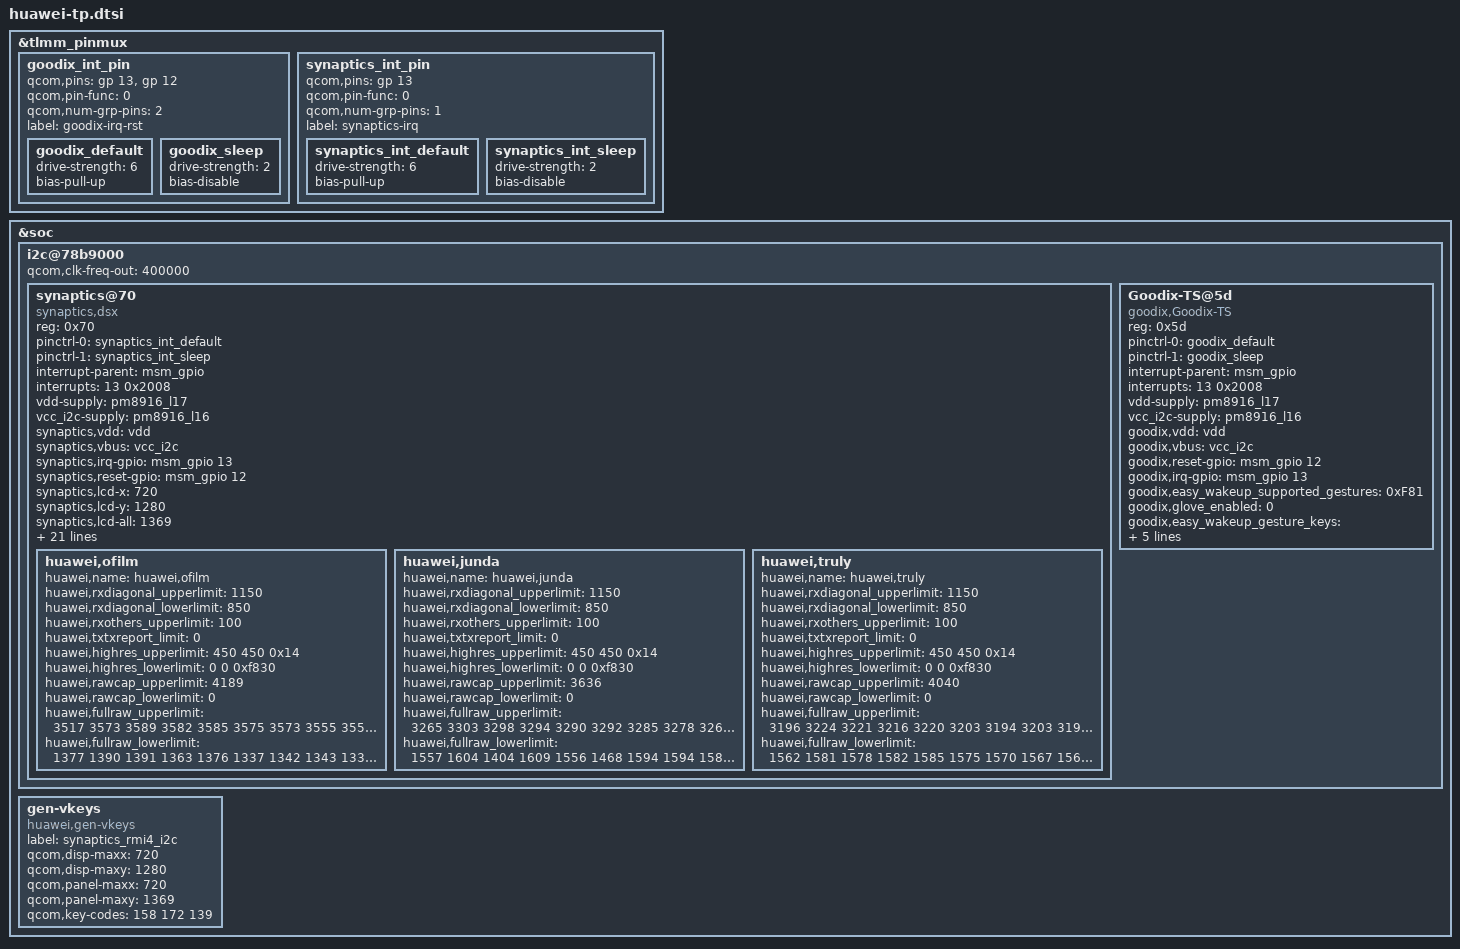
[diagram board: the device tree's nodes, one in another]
/*Add synaptics new driver "Synaptics DSX I2C V2.0"*/
/*Change i2c frepuence from 100kHZ to 400kHZ*/
/*Open fast-relax config for better gesture performance*/
/*Add doze wakeup threshold param for tempreture performance*/
/* Add the pinctrl for the irq and rst*/
&tlmm_pinmux {

	goodix_int_pin {
		qcom,pins = <&gp 13>,<&gp 12>;
		qcom,pin-func = <0>;
		qcom,num-grp-pins = <2>;
		label = "goodix-irq-rst";
		goodix_default: goodix_default {
			drive-strength = <6>;
			bias-pull-up;
		};
		goodix_sleep: goodix_sleep {
			drive-strength = <2>;
			bias-disable;
		};
	};
	synaptics_int_pin {
		qcom,pins = <&gp 13>;
		qcom,pin-func = <0>;
		qcom,num-grp-pins = <1>;
		label = "synaptics-irq";
		synaptics_int_default: synaptics_int_default {
			drive-strength = <6>;
			bias-pull-up;
		};
		synaptics_int_sleep: synaptics_int_sleep {
			drive-strength = <2>;
			bias-disable;
		};
	};
};
&soc {
	i2c@78b9000 { /* BLSP1 QUP5 */
		status = "ok";
		#address-cells = <1>;
		#size-cells = <0>;
		qcom,clk-freq-out = <400000>;
		synaptics@70 {
			compatible = "synaptics,dsx";
			reg = <0x70>;
			pinctrl-names = "active","sleep";
			pinctrl-0 = <&synaptics_int_default>;
			pinctrl-1 = <&synaptics_int_sleep>;
			interrupt-parent = <&msm_gpio>;
			interrupts = <13 0x2008>;
			vdd-supply = <&pm8916_l17>;
			vcc_i2c-supply = <&pm8916_l16>;
			/* Some of qcom's param will not be replaced by huawei in dtb, */
			/* just ignore them:such as "pinctrl-names","pinctrl-0","pinctrl-1", */
			/* "synaptics,display-coords","synaptics,panel-coords","synaptics,i2c-pull-up", */
			/* "synaptics,power-down","synaptics,disable-gpios"*/
			synaptics,vdd = "vdd";
			synaptics,vbus = "vcc_i2c";
			synaptics,irq-gpio = <&msm_gpio 13 0x2008>;
			synaptics,reset-gpio = <&msm_gpio 12 0x0>;

			synaptics,lcd-x = <720>;
			synaptics,lcd-y = <1280>;
			synaptics,lcd-all = <1369>;
			synaptics,virtual_keys = /* KeyCode CenterX CenterY Width Height */
				/* KEY_BACK */
				<158 142 1342 150 100
				/* KEY_HOME(172) */
				172 360 1342 150 100
				/* KEY_MENU */
				139 578 1342 150 100>;

			/* SYNAPTICS_WAKE_UP_GESTURE_FLAG:'1'->enabled,'0'->disabled */
			/*IC flash is not enough for holster,so fw del one gesture*/
			synaptics,gesture_enabled = <0>;
			/* Gestures that supported:                           */
			/* bit0  Double tap                                        */
			/* bit1  Single finger slide from left to right     */
			/* bit2  Single finger slide from right to left     */
			/* bit3  Single finger slide from top to bottom  */
			/* bit4  Single finger slide from bottom to top  */
			/* bit5  Double finger slide from top to bottom--disable for holster*/
			/* bit6  Single finger slide circle                     */
			/* bit7  Single finger write letter c                  */
			/* bit8  Single finger write letter e                  */
			/* bit9  Single finger write letter m                 */
			/* bit10 Single finger write letter w                 */
			/* bit11 Palm off screen                                */
			synaptics,easy_wakeup_supported_gestures = <0xF81>;

			/*Defination of report key value  for different gestures*/
			synaptics,easy_wakeup_gesture_keys = 
			<	143 /*0.Double tap:KEY_WAKEUP*/
				60 /*1.Single finger slide from left to right*/
				61 /*2.Single finger slide from right to left:KEY_F3*/
				62 /*3.Single finger slide from top to bottom*/
				63 /*4.Single finger slide from bottom to top:KEY_F5*/
				64 /*5.Single finger slide circle clockwise*/
				65 /*6.Single finger slide circle counter-clockwise*/
				66 /*7.Single finger write letter c*/
				67 /*8.Single finger write letter e:KEY_F9*/
				68 /*9.Single finger write letter m*/
				87 /*10.Single finger write letter w:KEY_F11*/
				88 /*11.Palm off screen*/
			>;

			/* Double-tap-zone defined by huawei */
			/* Shielded area is:1cm left,1cm right,3cm up,2cm down */
			huawei,dtz_x0 = <116>;
			huawei,dtz_y0 = <349>;
			huawei,dtz_x1 = <604>;
			huawei,dtz_y1 = <1047>;

			/* SYNAPTICS_GLOVE_FUNCTION_FLAG:'1'->enabled,'0'->disabled*/
			synaptics,glove_enabled = <0>;
			/*After reduce power-consumption by exit reduce mode,*/
			/*we have to reduce f-r rate to make sure gesture work fine*/
			synaptics,fast_relax_gesture = <12>;
			/*Holster support flag*/
			/*synaptics,holster_supported = <0>;*/
			/*dwt represent doze wakeup threshold in gesture mode*/
			synaptics,ofilm_dwt = <30>;
			synaptics,truly_dwt = <30>;
			synaptics,junda_dwt = <30>;

			synaptics,reset-on-status = <0>;
			synaptics,power-delay-ms = <160>;
			synaptics,reset-delay-ms = <100>;
			synaptics,reset-active-ms = <90>;
			synaptics,product_name = "g620S";

			/*capacitance self-adapt*/
			/*To adjust the cutting angle threshold to the maximum range*/
			huawei,ofilm {
				huawei,name = "huawei,ofilm";
				huawei,rxdiagonal_upperlimit = <1150>;
				huawei,rxdiagonal_lowerlimit = <850>;
				huawei,rxothers_upperlimit = <100>;
				huawei,txtxreport_limit = <0>;
				huawei,highres_upperlimit = <450 450 0x14>;/*0x14==20*/
				huawei,highres_lowerlimit = <0 0 0xf830>;/*0xf830==-2000*/
				huawei,rawcap_upperlimit = <4189>;
				huawei,rawcap_lowerlimit = <0>;

				huawei,fullraw_upperlimit =
					<3517 3573 3589 3582 3585 3575 3573 3555 3556 3554 3543 3520 4191 3894 3866 3902 3872 3831 3823 3836 3837 3801 3799 9999
					3578 3651 3654 3650 3658 3653 3638 3620 3623 3617 3608 3580 3671 3659 3655 3692 3706 3660 3664 3684 3682 3655 3673 3637
					3584 3653 3646 3647 3655 3634 3638 3621 3623 3620 3612 3581 3649 3638 3653 3672 3680 3645 3641 3660 3653 3641 3633 3633
					3586 3654 3651 3671 3684 3641 3636 3620 3619 3619 3611 3581 3625 3625 3651 3666 3676 3629 3636 3668 3655 3637 3646 3612
					3588 3656 3651 3688 3679 3638 3630 3617 3617 3619 3611 3589 3610 3611 3625 3634 3651 3619 3615 3654 3637 3606 3637 3578
					3598 3660 3688 3686 3653 3636 3634 3624 3623 3627 3614 3589 3591 3621 3619 3616 3625 3617 3603 3658 3617 3584 3604 3558
					3612 3682 3689 3681 3649 3650 3637 3625 3629 3634 3625 3599 3589 3614 3611 3607 3599 3589 3586 3636 3586 3584 3611 3611
					3615 3689 3697 3651 3662 3656 3651 3642 3641 3645 3628 3615 3581 3599 3602 3603 3597 3590 3562 3614 3597 3598 3593 3562
					3638 3692 3669 3660 3669 3666 3667 3647 3650 3647 3636 3617 3575 3601 3588 3599 3599 3578 3559 3594 3606 3567 3586 3533
					3628 3695 3689 3682 3686 3680 3685 3667 3669 3662 3654 3627 3585 3595 3584 3581 3582 3584 3584 3593 3567 3547 3578 3530
					3638 3719 3711 3703 3707 3689 3690 3682 3689 3680 3669 3653 3584 3591 3607 3590 3582 3606 3584 3582 3559 3565 3560 3559
					3660 3732 3727 3716 3721 3706 3712 3699 3711 3697 3686 3684 3588 3610 3617 3595 3593 3614 3582 3575 3577 3558 3559 3520
					3859 3819 3822 3794 3820 3816 3827 3819 3836 3828 3818 3853 3560 3571 3576 3546 3537 3565 3537 3529 3534 3503 3494 9999>;
				/* modify the lower limit of ofilm according the capacitance data*/
				huawei,fullraw_lowerlimit =
					<1377 1390 1391 1363 1376 1337 1342 1343 1335 1332 1316 1313 1616 1575 1552 1557 1544 1529 1531 1537 1517 1529 1511 0
					1421 1435 1438 1399 1396 1398 1382 1387 1370 1370 1367 1342 1474 1475 1459 1460 1454 1468 1459 1452 1459 1460 1457 1457
					1433 1442 1442 1414 1428 1401 1400 1388 1391 1372 1375 1358 1459 1452 1434 1445 1442 1448 1440 1443 1428 1442 1431 1524
					1420 1435 1439 1405 1410 1377 1386 1384 1376 1374 1358 1352 1424 1429 1412 1400 1401 1411 1384 1414 1396 1400 1407 1417
					1435 1450 1441 1421 1421 1397 1405 1397 1385 1376 1378 1361 1421 1414 1399 1411 1391 1407 1398 1407 1393 1406 1396 1396
					1424 1438 1433 1414 1419 1391 1396 1391 1384 1379 1370 1359 1391 1389 1378 1382 1379 1363 1363 1375 1363 1377 1362 1382
					1474 1487 1480 1464 1456 1447 1428 1429 1417 1410 1410 1380 1403 1406 1398 1403 1392 1396 1382 1390 1381 1384 1372 1514
					1452 1463 1459 1432 1458 1425 1422 1409 1419 1391 1394 1379 1379 1368 1350 1363 1358 1368 1356 1358 1347 1358 1342 1372
					1468 1483 1489 1454 1453 1459 1439 1442 1421 1422 1419 1396 1379 1384 1371 1370 1361 1365 1363 1356 1365 1364 1360 1361
					1504 1526 1515 1508 1504 1487 1491 1483 1478 1472 1463 1446 1393 1401 1385 1386 1377 1368 1364 1381 1367 1366 1376 1383
					1502 1522 1517 1496 1493 1487 1482 1468 1470 1451 1455 1441 1355 1365 1356 1356 1336 1362 1323 1358 1351 1352 1330 1459
					1495 1523 1518 1505 1510 1498 1497 1485 1478 1473 1473 1458 1381 1356 1352 1363 1334 1322 1326 1332 1319 1333 1317 1329
					1537 1558 1566 1540 1554 1526 1535 1536 1530 1521 1514 1517 1344 1342 1323 1335 1328 1321 1315 1326 1310 1319 1290 0>;
			};
			huawei,junda {
				huawei,name = "huawei,junda";
				huawei,rxdiagonal_upperlimit = <1150>;
				huawei,rxdiagonal_lowerlimit = <850>;
				huawei,rxothers_upperlimit = <100>;
				huawei,txtxreport_limit = <0>;
				huawei,highres_upperlimit = <450 450 0x14>;/*0x14==20*/
				huawei,highres_lowerlimit = <0 0 0xf830>;/*0xf830==-2000*/
				huawei,rawcap_upperlimit = <3636>;
				huawei,rawcap_lowerlimit = <0>;

				huawei,fullraw_upperlimit =
					<3265 3303 3298 3294 3290 3292 3285 3278 3265 3283 3282 3270 3638 3565 3543 3551 3529 3519 3520 3517 3504 3502 3503 9999 
					3282 3317 3315 3304 3303 3291 3296 3286 3269 3290 3294 3266 3333 3331 3331 3330 3335 3331 3328 3326 3322 3325 3331 3253 
					3283 3315 3316 3305 3305 3296 3294 3292 3269 3285 3292 3265 3315 3316 3309 3309 3317 3318 3312 3303 3307 3305 3316 3338 
					3289 3325 3329 3318 3318 3303 3303 3298 3274 3296 3302 3273 3303 3303 3292 3303 3303 3298 3303 3298 3295 3299 3304 3221 
					3289 3330 3325 3321 3316 3302 3303 3296 3274 3296 3303 3278 3296 3295 3274 3292 3282 3291 3292 3289 3281 3285 3290 3190 
					3291 3328 3328 3318 3315 3302 3308 3302 3278 3299 3307 3285 3289 3283 3273 3282 3273 3277 3281 3276 3266 3268 3274 3199 
					3300 3338 3338 3328 3320 3312 3312 3309 3287 3304 3312 3292 3278 3272 3261 3268 3264 3268 3265 3259 3251 3257 3269 3363 
					3315 3352 3350 3339 3334 3326 3333 3321 3300 3317 3324 3296 3270 3266 3253 3266 3259 3268 3261 3256 3252 3251 3259 3179 
					3331 3360 3357 3352 3344 3337 3342 3331 3311 3326 3325 3303 3261 3259 3251 3261 3251 3263 3259 3250 3251 3250 3256 3156 
					3341 3372 3372 3367 3357 3348 3356 3347 3321 3337 3338 3315 3257 3259 3250 3260 3250 3259 3251 3248 3246 3247 3251 3191 
					3352 3389 3386 3378 3372 3363 3369 3361 3334 3350 3348 3330 3266 3269 3265 3269 3259 3264 3257 3253 3250 3251 3261 3338 
					3356 3394 3396 3386 3385 3372 3381 3368 3343 3360 3359 3346 3266 3269 3257 3276 3265 3268 3263 3256 3251 3253 3261 3159 
					3468 3520 3532 3529 3526 3508 3520 3515 3487 3513 3515 3543 3265 3270 3261 3282 3274 3276 3269 3261 3259 3259 3260 9999>;

				huawei,fullraw_lowerlimit =
					<1557 1604 1404 1609 1556 1468 1594 1594 1589 1599 1598 1590 1730 1721 1709 1713 1709 1699 1699 1698 1668 1697 1708 0 
					1550 1603 1406 1608 1561 1476 1596 1593 1589 1597 1598 1590 1615 1603 1597 1601 1601 1599 1600 1599 1569 1602 1618 1580 
					1556 1603 1407 1607 1562 1474 1602 1596 1591 1599 1598 1591 1599 1602 1589 1594 1593 1589 1589 1590 1561 1594 1608 1633 
					1555 1605 1410 1612 1568 1481 1607 1600 1594 1601 1601 1590 1590 1598 1585 1589 1589 1585 1583 1584 1557 1588 1604 1567 
					1559 1605 1411 1611 1569 1484 1611 1602 1594 1602 1599 1594 1582 1593 1585 1586 1586 1578 1575 1576 1547 1585 1601 1550 
					1563 1604 1413 1609 1575 1489 1613 1603 1595 1601 1603 1596 1576 1591 1584 1585 1586 1577 1575 1576 1538 1584 1594 1559 
					1566 1604 1414 1610 1582 1498 1610 1604 1596 1603 1604 1596 1569 1589 1582 1587 1587 1579 1575 1577 1532 1583 1593 1648 
					1526 1549 1421 1538 1532 1505 1526 1517 1509 1510 1515 1505 1498 1501 1498 1512 1510 1509 1503 1507 1504 1510 1514 1467 
					1580 1610 1506 1610 1611 1568 1611 1608 1603 1604 1608 1603 1559 1586 1579 1585 1587 1581 1580 1578 1528 1578 1587 1543 
					1585 1620 1591 1612 1614 1612 1616 1613 1606 1608 1612 1608 1556 1587 1577 1584 1585 1582 1578 1577 1524 1580 1587 1561 
					1589 1624 1598 1615 1617 1616 1620 1615 1608 1611 1617 1612 1558 1586 1578 1585 1582 1581 1579 1575 1527 1575 1589 1624 
					1594 1629 1606 1621 1623 1623 1623 1620 1616 1615 1622 1621 1554 1585 1576 1584 1579 1583 1579 1575 1529 1573 1572 1536 
					1666 1695 1680 1702 1701 1694 1699 1694 1692 1694 1685 1647 1559 1583 1455 1586 1575 1581 1577 1575 1529 1570 1559 0 >;
			};
			huawei,truly {
				huawei,name = "huawei,truly";
				huawei,rxdiagonal_upperlimit = <1150>;
				huawei,rxdiagonal_lowerlimit = <850>;
				huawei,rxothers_upperlimit = <100>;
				huawei,txtxreport_limit = <0>;
				huawei,highres_upperlimit = <450 450 0x14>;/*0x14==20*/
				huawei,highres_lowerlimit = <0 0 0xf830>;/*0xf830==-2000*/
				huawei,rawcap_upperlimit = <4040>;
				huawei,rawcap_lowerlimit = <0>;

				huawei,fullraw_upperlimit =
					<3196 3224 3221 3216 3220 3203 3194 3203 3190 3192 3186 3178 3625 3508 3484 3482 3455 3434 3432 3425 3421 3415 3395 9999 
					3194 3217 3218 3214 3217 3195 3185 3194 3185 3178 3181 3172 3268 3253 3257 3268 3250 3239 3237 3231 3225 3226 3218 3194 
					3204 3233 3231 3222 3225 3201 3198 3199 3188 3190 3183 3173 3248 3233 3240 3247 3221 3211 3217 3213 3207 3204 3194 3251 
					3208 3244 3230 3234 3231 3214 3214 3207 3205 3209 3199 3186 3231 3218 3225 3229 3208 3211 3208 3214 3196 3195 3194 3186 
					3214 3248 3234 3239 3233 3218 3218 3214 3203 3201 3205 3198 3226 3208 3212 3208 3198 3199 3199 3209 3191 3196 3192 3156 
					3216 3248 3246 3246 3243 3216 3222 3216 3207 3209 3208 3199 3209 3201 3208 3198 3194 3191 3190 3200 3181 3183 3174 3179 
					3230 3259 3253 3252 3257 3237 3225 3225 3214 3224 3211 3208 3213 3208 3208 3199 3188 3185 3183 3196 3170 3175 3165 3295 
					3242 3273 3253 3259 3272 3246 3234 3231 3234 3234 3221 3213 3205 3198 3198 3192 3186 3186 3175 3188 3160 3159 3153 3162 
					3248 3276 3273 3269 3279 3250 3242 3246 3244 3250 3233 3225 3201 3188 3192 3190 3177 3178 3165 3179 3153 3151 3152 3130 
					3259 3285 3286 3277 3281 3263 3251 3257 3251 3250 3244 3229 3194 3186 3194 3192 3168 3173 3162 3172 3160 3157 3151 3164 
					3274 3296 3298 3283 3294 3273 3264 3273 3269 3260 3253 3251 3186 3183 3182 3188 3165 3165 3161 3177 3155 3152 3144 3307 
					3285 3308 3304 3304 3317 3291 3274 3287 3278 3279 3257 3660 3178 3179 3175 3178 3156 3159 3152 3165 3144 3140 3133 3103 
					3638 3506 3487 3485 3497 3468 3454 3460 3447 3454 3435 4039 3200 3204 3201 3205 3181 3177 3174 3191 3164 3156 3153 9999>;

				huawei,fullraw_lowerlimit =
					<1562 1581 1578 1582 1585 1575 1570 1567 1569 1564 1570 1563 1774 1706 1692 1696 1683 1664 1669 1673 1671 1668 1673 0 
					1557 1575 1575 1575 1577 1568 1561 1564 1567 1559 1566 1557 1589 1582 1583 1586 1579 1564 1570 1575 1575 1575 1581 1572 
					1555 1575 1575 1575 1578 1571 1561 1568 1571 1560 1565 1557 1577 1576 1575 1575 1572 1554 1561 1566 1571 1570 1578 1605 
					1555 1577 1581 1577 1580 1571 1565 1571 1570 1561 1562 1561 1566 1571 1573 1571 1568 1553 1559 1563 1568 1569 1575 1558 
					1559 1576 1580 1580 1580 1573 1568 1570 1571 1561 1564 1561 1563 1565 1568 1569 1568 1553 1557 1562 1568 1566 1571 1541 
					1561 1578 1581 1580 1582 1575 1568 1570 1571 1563 1568 1561 1560 1564 1564 1568 1565 1554 1559 1561 1565 1561 1566 1559 
					1565 1583 1585 1582 1582 1578 1571 1573 1574 1564 1572 1568 1556 1564 1564 1566 1566 1554 1554 1559 1564 1557 1565 1630 
					1563 1582 1583 1583 1580 1576 1573 1575 1573 1568 1573 1569 1549 1554 1551 1556 1558 1546 1551 1556 1554 1550 1558 1549 
					1568 1585 1585 1585 1585 1579 1575 1579 1578 1574 1577 1574 1552 1553 1546 1553 1556 1547 1547 1547 1555 1550 1558 1531 
					1573 1585 1586 1587 1586 1580 1579 1578 1579 1576 1585 1580 1547 1549 1543 1550 1555 1545 1547 1547 1553 1547 1555 1552 
					1575 1587 1587 1588 1588 1586 1580 1583 1588 1583 1589 1584 1546 1545 1543 1546 1550 1537 1538 1543 1547 1544 1549 1609 
					1588 1596 1592 1596 1592 1593 1587 1591 1593 1588 1596 1592 1547 1549 1546 1547 1546 1532 1535 1540 1545 1542 1549 1524 
					1729 1692 1683 1683 1684 1683 1680 1682 1682 1678 1686 1693 1555 1561 1558 1558 1554 1544 1546 1547 1555 1547 1554 0>;
			};
		};
	};
	/*Add goodix new driver "gt9xx V1.8"*/
	i2c@78b9000 {
		status = "ok";
		Goodix-TS@5d {
			compatible = "goodix,Goodix-TS";
			reg = <0x5d>;
			pinctrl-names = "default","sleep";
			pinctrl-0 = <&goodix_default>;
			pinctrl-1 = <&goodix_sleep>;
			interrupt-parent = <&msm_gpio>;
			interrupts = <13 0x2008>;
		
			vdd-supply = <&pm8916_l17>;
			vcc_i2c-supply = <&pm8916_l16>;

			goodix,vdd = "vdd";
			goodix,vbus = "vcc_i2c";
			goodix,reset-gpio = <&msm_gpio 12 0x0>;
			goodix,irq-gpio = <&msm_gpio 13 0x2008>;
			goodix,easy_wakeup_supported_gestures = <0xF81>;
			goodix,glove_enabled = <0>;
			/* Gestures that supported:                           */
			/* bit0  Double tap                                        */
			/* bit1  Single finger slide from left to right     */
			/* bit2  Single finger slide from right to left     */
			/* bit3  Single finger slide from top to bottom  */
			/* bit4  Single finger slide from bottom to top  */
			/* bit5  Double finger slide from top to bottom--disable for holster*/
			/* bit6  Single finger slide circle                     */
			/* bit7  Single finger write letter c                  */
			/* bit8  Single finger write letter e                  */
			/* bit9  Single finger write letter m                 */
			/* bit10 Single finger write letter w                 */
			/* bit11 Palm off screen                                */

			/*Defination of report key value  for different gestures*/
			goodix,easy_wakeup_gesture_keys = 
			<	59 /*0.Double tap:KEY_F1*/
				60 /*1.Single finger slide from left to right*/
				61 /*2.Single finger slide from right to left:KEY_F3*/
				62 /*3.Single finger slide from top to bottom*/
				63 /*4.Single finger slide from bottom to top:KEY_F5*/
				64 /*5.Single finger slide circle clockwise*/
				65 /*6.Single finger slide circle counter-clockwise*/
				66 /*7.Single finger write letter c*/
				67 /*8.Single finger write letter e:KEY_F9*/
				68 /*9.Single finger write letter m*/
				87 /*10.Single finger write letter w:KEY_F11*/
				88 /*11.Palm off screen*/
			>;
			/*add the rawdata limit for metal mesh */
			/*modify the rawdata limit for new pattern*/
			huawei,fullraw_upperlimit =
				<2613 3801 3612 2296 2289 3609 3636 2296 2360 3660 3708 2419 2450 3744 3796 2495 2550 3769 9999 9999 
				2848 4054 3730 2410 2390 3703 3747 2430 2510 3781 3937 2595 2690 4057 4218 2810 2980 4372 9999 9999 
				2832 4062 3736 2415 2398 3714 3768 2385 2449 3810 3937 2523 2613 4047 4224 2751 2946 4602 5268 9999
				2869 4047 3739 2450 2416 3693 3738 2386 2433 3786 3969 2553 2644 4063 4237 2779 2979 4590 9999 9999 
				2949 4116 3808 2584 2530 3780 3817 2449 2502 3846 3978 2592 2670 4083 4257 2803 3001 4608 9999 9999 
				2838 4093 3853 2506 2448 3762 3804 2404 2461 3828 3930 2554 2643 4041 4200 2772 2952 4369 9999 9999 
				2958 4120 3855 2569 2506 3759 3805 2491 2536 3852 3973 2616 2715 4081 4258 2847 3037 4636 5509 9999
				3028 4174 3832 2577 2499 3805 3858 2517 2560 3903 4005 2641 2740 4135 4314 2877 3072 4671 9999 9999 
				3079 4224 3880 2635 2619 3846 3906 2653 2670 3946 4045 2751 2847 4159 4323 2968 3159 4485 9999 9999 
				3169 4224 3868 2682 2661 3912 3928 2689 2733 3964 4108 2815 2919 4219 4378 3052 3271 4759 5188 9999
				3207 4356 3925 2710 2680 3912 3964 2701 2745 4020 4128 2815 2914 4248 4443 3051 3279 4879 9999 9999 >;

			huawei,fullraw_lowerlimit =
				<905 1319 1255 792 783 1251 1260 791 805 1274 1295 823 835 1299 1316 849 867 1315 0 0 
				983 1400 1295 832 815 1290 1296 827 843 1323 1365 875 907 1407 1465 955 875 1140 0 0 
				980 1400 1294 838 818 1287 1306 828 849 1325 1375 877 909 1415 1479 959 1026 1612 1646 0 
				989 1404 1310 838 824 1296 1314 838 856 1332 1379 882 914 1414 1470 959 1026 1591 0 0 
				1009 1418 1323 855 829 1309 1328 857 881 1346 1390 900 934 1428 1488 983 1051 1610 0 0 
				988 1347 1319 846 834 1311 1322 835 854 1341 1385 879 910 1420 1477 954 1019 1538 0 0 
				1013 1440 1331 870 855 1317 1334 869 881 1355 1393 909 944 1436 1499 992 1060 1629 1770 0 
				1033 1449 1344 885 868 1329 1343 878 894 1372 1403 918 951 1443 1502 997 1065 1622 0 0 
				1029 1442 1337 881 860 1323 1343 872 889 1357 1398 917 948 1437 1494 995 1059 1552 0 0 
				1061 1458 1340 900 879 1336 1347 891 918 1365 1413 945 976 1452 1512 1027 1100 1651 1664 0 
				1067 1480 1357 908 881 1341 1361 888 910 1383 1439 947 981 1481 1551 1032 1110 1697 0 0 >;
		};
	};
	/*To disable gen-vkeys.c probe,avoid generate kobject*/
	gen-vkeys {
		compatible = "huawei,gen-vkeys";
		label = "synaptics_rmi4_i2c";
		qcom,disp-maxx = <720>;
		qcom,disp-maxy = <1280>;
		qcom,panel-maxx = <720>;
		qcom,panel-maxy = <1369>;
		qcom,key-codes = <158 172 139>;
	};

};
